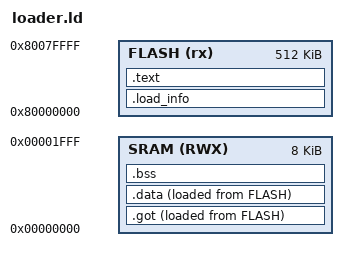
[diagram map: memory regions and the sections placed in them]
/* Copyright 2018 Google LLC
 *
 * Licensed under the Apache License, Version 2.0 (the "License");
 * you may not use this file except in compliance with the License.
 * You may obtain a copy of the License at
 *
 *     https://www.apache.org/licenses/LICENSE-2.0
 *
 * Unless required by applicable law or agreed to in writing, software
 * distributed under the License is distributed on an "AS IS" BASIS,
 * WITHOUT WARRANTIES OR CONDITIONS OF ANY KIND, either express or implied.
 * See the License for the specific language governing permissions and
 * limitations under the License.
 */

ENTRY(_start)

MEMORY {
    FLASH (rx) : ORIGIN = 0x80000000, LENGTH = 0x00080000
    SRAM (RWX) : ORIGIN = 0x00000000, LENGTH = 0x00002000
}

SECTIONS {
/* Load information, used by runtime to load app */
    .load_info :
    {
        KEEP(*(.load_info))
    } > FLASH =0xFF

/* Text section, Code! */
    .text :
    {
        _text = .;
        KEEP (*(.start))
        *(.text*)
        *(.rodata*)
        KEEP (*(.syscalls))
        _etext = .;
    } > FLASH =0xFF

/* Global Offset Table */
    .got :
    {
        _got = .;
        *(.got*)
        _egot = .;
        _plt = .;
        *(.got.plt*)
        _eplt = .;
    } > SRAM AT > FLASH

/* Data section, static initialized variables
 *  Note: This is placed in Flash after the text section, but needs to be
 *  moved to SRAM at runtime
 */
    .data :
    {
        _data = .;
        *(.data*)
        _edata = .;
    } > SRAM AT > FLASH

/* BSS section, static uninitialized variables */
    .bss :
    {
        _bss = .;
        *(.bss*)
        *(COMMON)
        _ebss = .;
    } > SRAM
}
